# ioat91sam3s4 register map
Registers are 32-bit, access not given, no defined reset value unless marked. A register's access mark holds for its fields unless they carry their own. Addresses are absolute; registers are grouped by the start of their names; [hi:lo] are bit positions; {n}, {i} and the like mark numbered series.

## PIOB
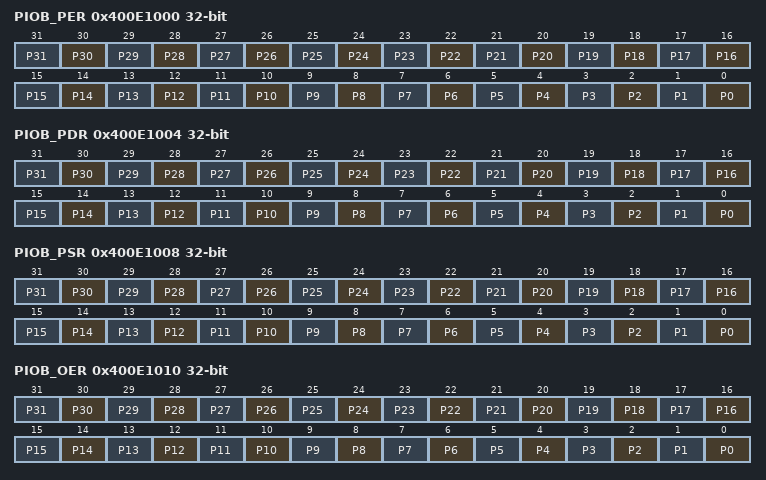
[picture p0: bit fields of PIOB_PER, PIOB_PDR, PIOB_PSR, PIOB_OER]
0x400E1000 PIOB_PER
  [n] P{n} (n=0..31)
0x400E1004 PIOB_PDR
  [n] P{n} (n=0..31)
0x400E1008 PIOB_PSR
  [n] P{n} (n=0..31)
0x400E1010 PIOB_OER
  [n] P{n} (n=0..31)
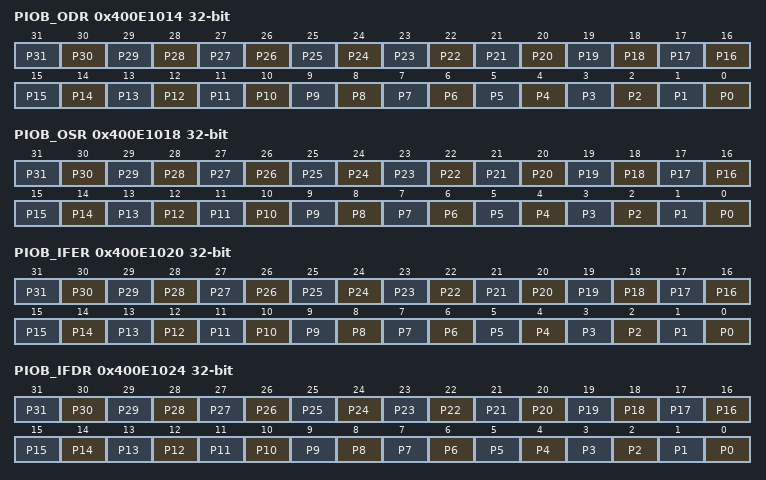
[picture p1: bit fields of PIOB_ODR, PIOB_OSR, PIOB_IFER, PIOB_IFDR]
0x400E1014 PIOB_ODR
  [n] P{n} (n=0..31)
0x400E1018 PIOB_OSR
  [n] P{n} (n=0..31)
0x400E1020 PIOB_IFER
  [n] P{n} (n=0..31)
0x400E1024 PIOB_IFDR
  [n] P{n} (n=0..31)
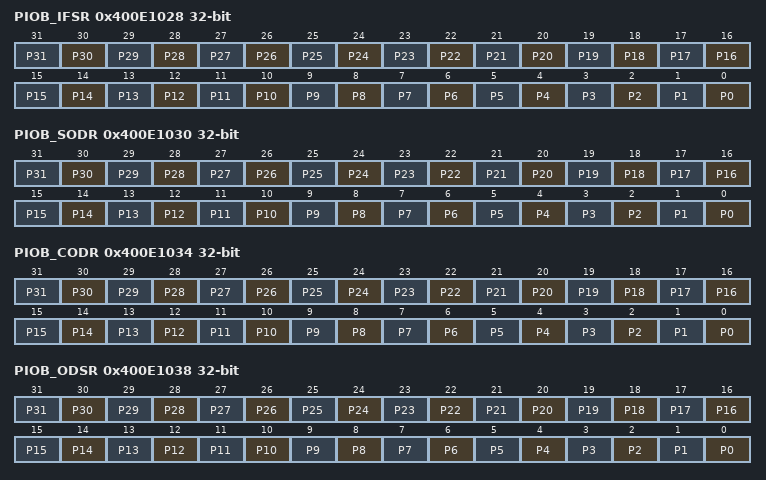
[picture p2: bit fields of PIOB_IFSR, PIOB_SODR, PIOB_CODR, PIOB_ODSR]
0x400E1028 PIOB_IFSR
  [n] P{n} (n=0..31)
0x400E1030 PIOB_SODR
  [n] P{n} (n=0..31)
0x400E1034 PIOB_CODR
  [n] P{n} (n=0..31)
0x400E1038 PIOB_ODSR
  [n] P{n} (n=0..31)
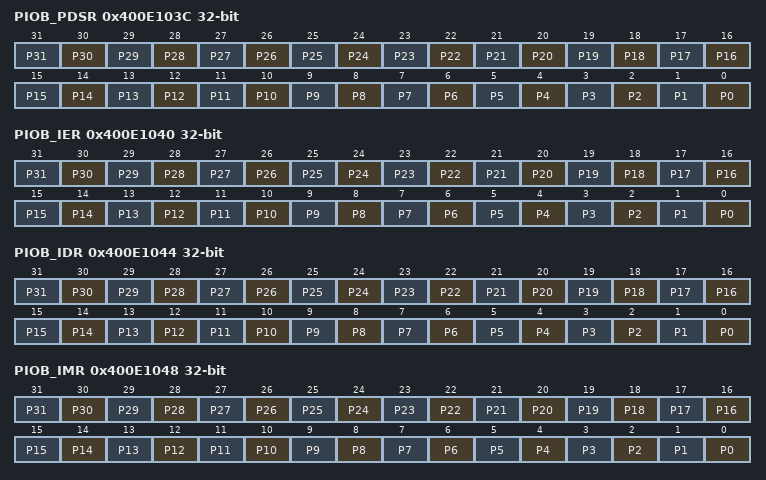
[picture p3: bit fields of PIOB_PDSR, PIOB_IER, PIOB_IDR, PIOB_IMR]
0x400E103C PIOB_PDSR
  [n] P{n} (n=0..31)
0x400E1040 PIOB_IER
  [n] P{n} (n=0..31)
0x400E1044 PIOB_IDR
  [n] P{n} (n=0..31)
0x400E1048 PIOB_IMR
  [n] P{n} (n=0..31)
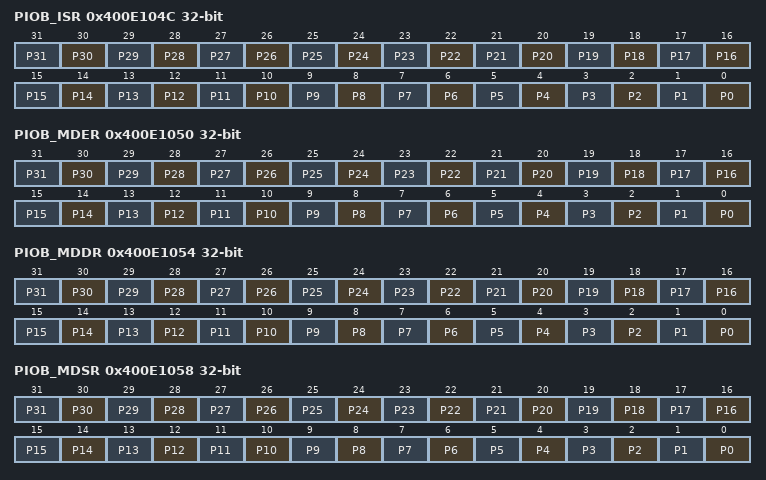
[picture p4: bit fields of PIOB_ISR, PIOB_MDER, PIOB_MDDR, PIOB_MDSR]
0x400E104C PIOB_ISR
  [n] P{n} (n=0..31)
0x400E1050 PIOB_MDER
  [n] P{n} (n=0..31)
0x400E1054 PIOB_MDDR
  [n] P{n} (n=0..31)
0x400E1058 PIOB_MDSR
  [n] P{n} (n=0..31)
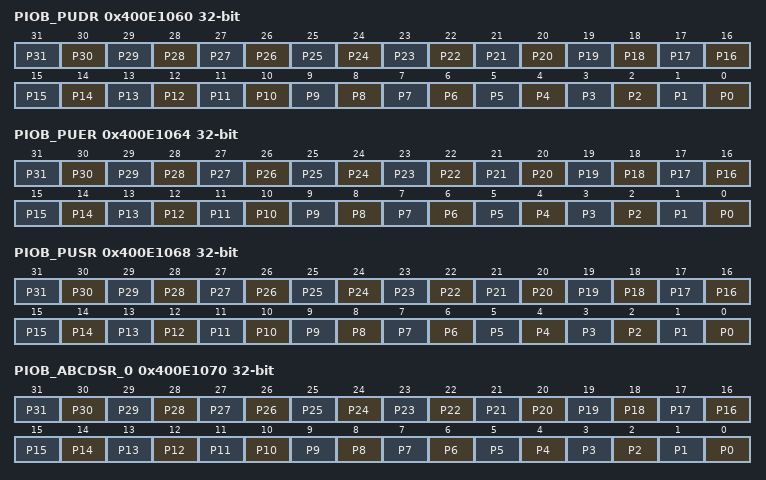
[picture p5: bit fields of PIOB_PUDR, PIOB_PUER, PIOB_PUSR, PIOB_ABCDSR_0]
0x400E1060 PIOB_PUDR
  [n] P{n} (n=0..31)
0x400E1064 PIOB_PUER
  [n] P{n} (n=0..31)
0x400E1068 PIOB_PUSR
  [n] P{n} (n=0..31)
0x400E1070 PIOB_ABCDSR_0
  [n] P{n} (n=0..31)
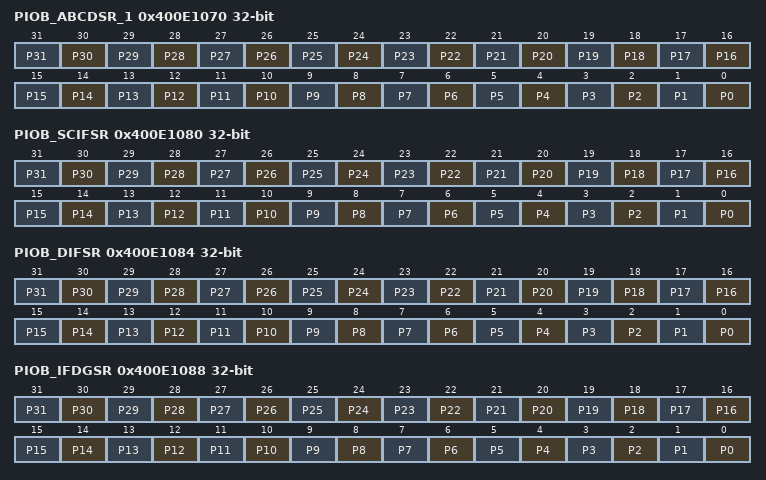
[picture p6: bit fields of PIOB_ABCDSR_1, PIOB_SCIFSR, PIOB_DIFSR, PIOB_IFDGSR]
0x400E1070 PIOB_ABCDSR_1
  [n] P{n} (n=0..31)
0x400E1080 PIOB_SCIFSR
  [n] P{n} (n=0..31)
0x400E1084 PIOB_DIFSR
  [n] P{n} (n=0..31)
0x400E1088 PIOB_IFDGSR
  [n] P{n} (n=0..31)
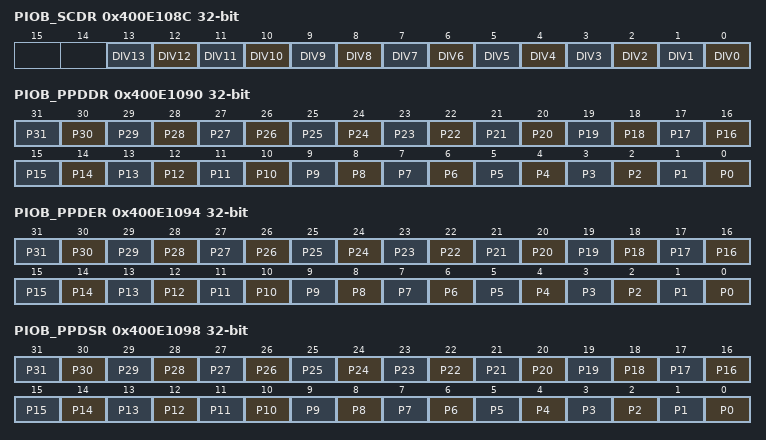
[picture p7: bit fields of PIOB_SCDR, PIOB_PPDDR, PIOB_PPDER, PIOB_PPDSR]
0x400E108C PIOB_SCDR
  [n] DIV{n} (n=0..13)
0x400E1090 PIOB_PPDDR
  [n] P{n} (n=0..31)
0x400E1094 PIOB_PPDER
  [n] P{n} (n=0..31)
0x400E1098 PIOB_PPDSR
  [n] P{n} (n=0..31)
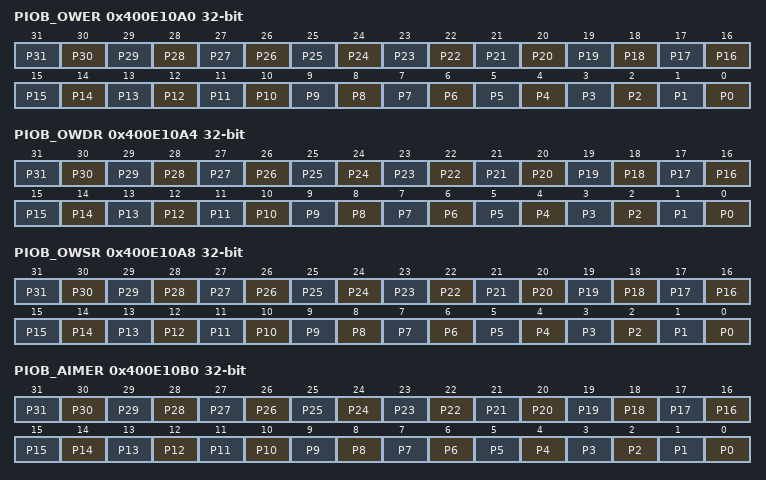
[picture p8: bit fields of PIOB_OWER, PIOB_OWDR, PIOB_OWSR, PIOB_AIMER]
0x400E10A0 PIOB_OWER
  [n] P{n} (n=0..31)
0x400E10A4 PIOB_OWDR
  [n] P{n} (n=0..31)
0x400E10A8 PIOB_OWSR
  [n] P{n} (n=0..31)
0x400E10B0 PIOB_AIMER
  [n] P{n} (n=0..31)
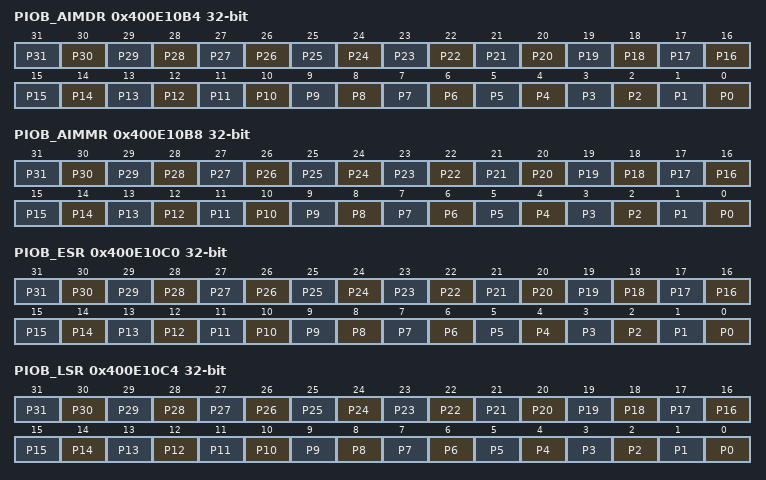
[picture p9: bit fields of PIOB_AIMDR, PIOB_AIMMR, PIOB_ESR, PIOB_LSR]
0x400E10B4 PIOB_AIMDR
  [n] P{n} (n=0..31)
0x400E10B8 PIOB_AIMMR
  [n] P{n} (n=0..31)
0x400E10C0 PIOB_ESR
  [n] P{n} (n=0..31)
0x400E10C4 PIOB_LSR
  [n] P{n} (n=0..31)
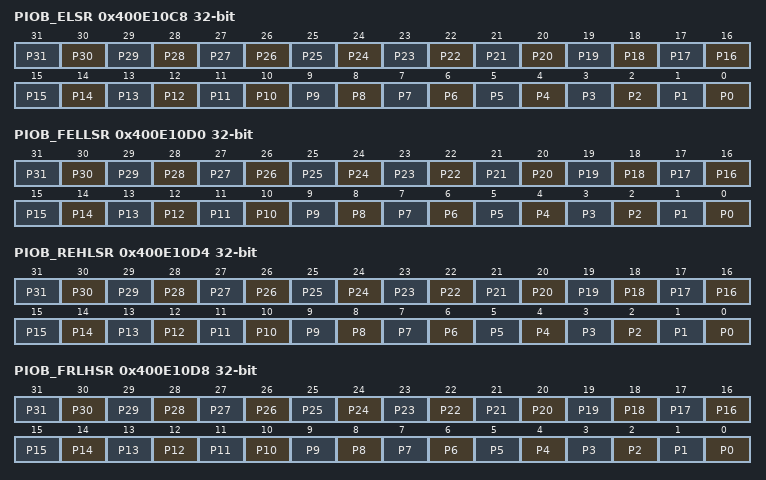
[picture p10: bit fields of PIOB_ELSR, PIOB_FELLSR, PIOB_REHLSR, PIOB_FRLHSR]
0x400E10C8 PIOB_ELSR
  [n] P{n} (n=0..31)
0x400E10D0 PIOB_FELLSR
  [n] P{n} (n=0..31)
0x400E10D4 PIOB_REHLSR
  [n] P{n} (n=0..31)
0x400E10D8 PIOB_FRLHSR
  [n] P{n} (n=0..31)
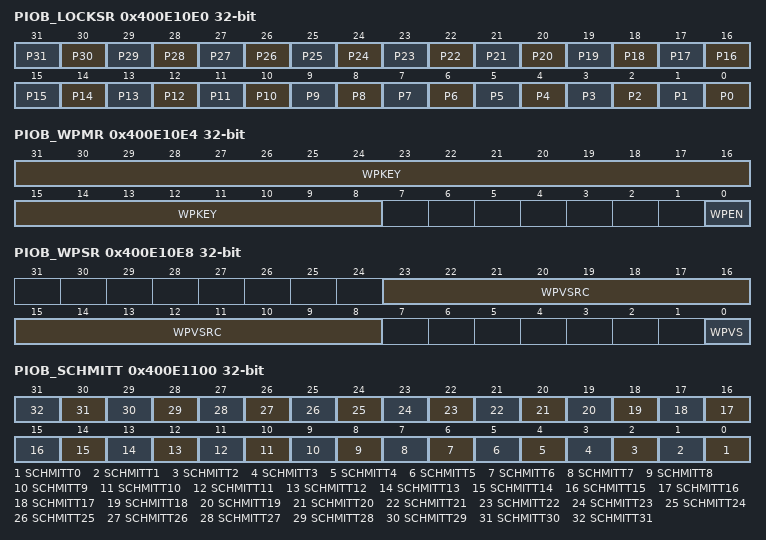
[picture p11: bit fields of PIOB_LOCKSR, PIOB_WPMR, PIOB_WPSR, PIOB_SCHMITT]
0x400E10E0 PIOB_LOCKSR
  [n] P{n} (n=0..31)
0x400E10E4 PIOB_WPMR
  [31:8] WPKEY, [0] WPEN
0x400E10E8 PIOB_WPSR
  [23:8] WPVSRC, [0] WPVS
0x400E1100 PIOB_SCHMITT
  [n] SCHMITT{n} (n=0..31)
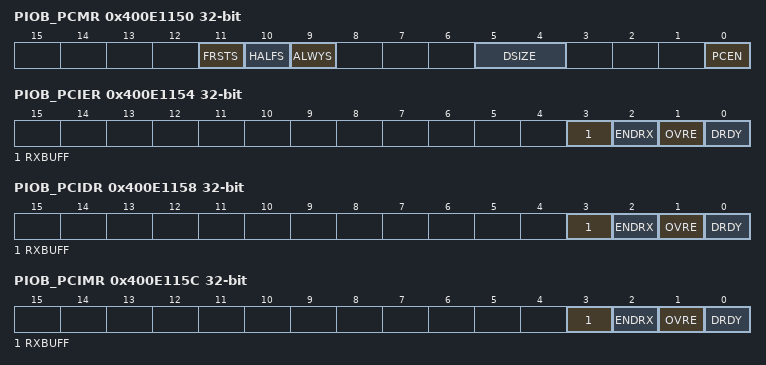
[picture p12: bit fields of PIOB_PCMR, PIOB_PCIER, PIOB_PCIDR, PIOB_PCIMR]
0x400E1150 PIOB_PCMR
  [11] FRSTS, [10] HALFS, [9] ALWYS, [5:4] DSIZE, [0] PCEN
0x400E1154 PIOB_PCIER
  [3] RXBUFF, [2] ENDRX, [1] OVRE, [0] DRDY
0x400E1158 PIOB_PCIDR
  [3] RXBUFF, [2] ENDRX, [1] OVRE, [0] DRDY
0x400E115C PIOB_PCIMR
  [3] RXBUFF, [2] ENDRX, [1] OVRE, [0] DRDY
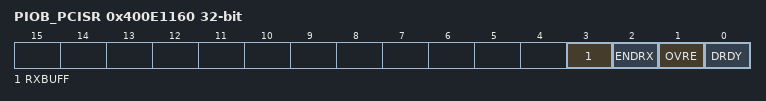
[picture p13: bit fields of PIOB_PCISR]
0x400E1160 PIOB_PCISR
  [3] RXBUFF, [2] ENDRX, [1] OVRE, [0] DRDY
0x400E1164 PIOB_PCRHR
  [31:0] RDATA

## PIOC
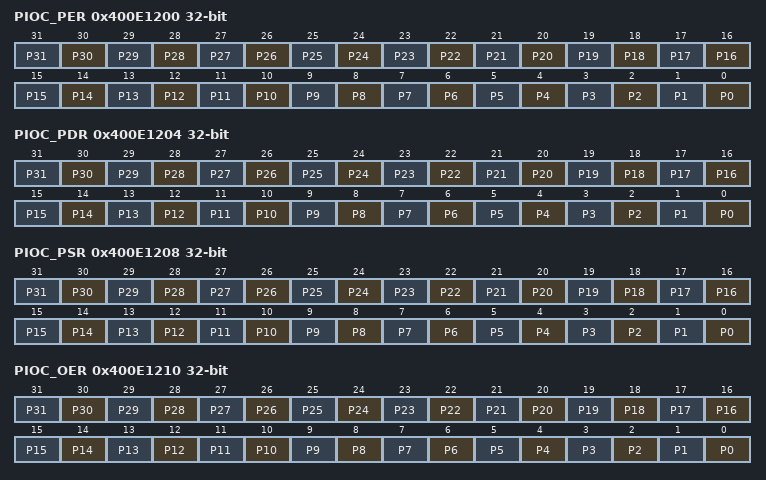
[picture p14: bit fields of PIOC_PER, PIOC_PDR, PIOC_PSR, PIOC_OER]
0x400E1200 PIOC_PER
  [n] P{n} (n=0..31)
0x400E1204 PIOC_PDR
  [n] P{n} (n=0..31)
0x400E1208 PIOC_PSR
  [n] P{n} (n=0..31)
0x400E1210 PIOC_OER
  [n] P{n} (n=0..31)
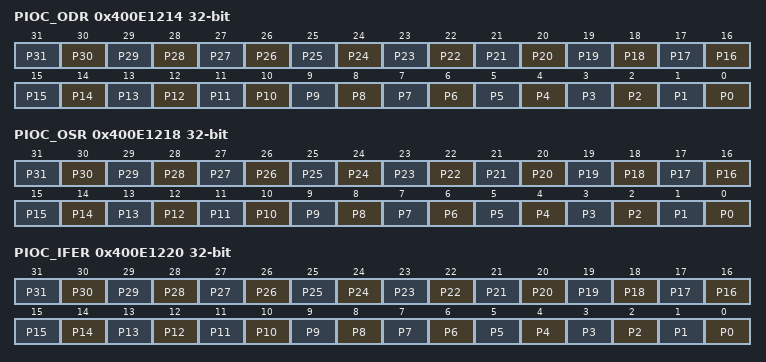
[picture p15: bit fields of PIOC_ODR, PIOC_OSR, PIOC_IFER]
0x400E1214 PIOC_ODR
  [n] P{n} (n=0..31)
0x400E1218 PIOC_OSR
  [n] P{n} (n=0..31)
0x400E1220 PIOC_IFER
  [n] P{n} (n=0..31)
0x400E1224 PIOC_IFDR
  [n] P{n} (n=0..31)
0x400E1228 PIOC_IFSR
  [n] P{n} (n=0..31)
0x400E1230 PIOC_SODR
  [n] P{n} (n=0..31)
0x400E1234 PIOC_CODR
  [n] P{n} (n=0..31)
0x400E1238 PIOC_ODSR
  [n] P{n} (n=0..31)
0x400E123C PIOC_PDSR
  [n] P{n} (n=0..31)
0x400E1240 PIOC_IER
  [n] P{n} (n=0..31)
0x400E1244 PIOC_IDR
  [n] P{n} (n=0..31)
0x400E1248 PIOC_IMR
  [n] P{n} (n=0..31)
0x400E124C PIOC_ISR
  [n] P{n} (n=0..31)
0x400E1250 PIOC_MDER
  [n] P{n} (n=0..31)
0x400E1254 PIOC_MDDR
  [n] P{n} (n=0..31)
0x400E1258 PIOC_MDSR
  [n] P{n} (n=0..31)
0x400E1260 PIOC_PUDR
  [n] P{n} (n=0..31)
0x400E1264 PIOC_PUER
  [n] P{n} (n=0..31)
0x400E1268 PIOC_PUSR
  [n] P{n} (n=0..31)
0x400E1270 PIOC_ABCDSR_0
  [n] P{n} (n=0..31)
0x400E1270 PIOC_ABCDSR_1
  [n] P{n} (n=0..31)
0x400E1280 PIOC_SCIFSR
  [n] P{n} (n=0..31)
0x400E1284 PIOC_DIFSR
  [n] P{n} (n=0..31)
0x400E1288 PIOC_IFDGSR
  [n] P{n} (n=0..31)
0x400E128C PIOC_SCDR
  [n] DIV{n} (n=0..13)
0x400E1290 PIOC_PPDDR
  [n] P{n} (n=0..31)
0x400E1294 PIOC_PPDER
  [n] P{n} (n=0..31)
0x400E1298 PIOC_PPDSR
  [n] P{n} (n=0..31)
0x400E12A0 PIOC_OWER
  [n] P{n} (n=0..31)
0x400E12A4 PIOC_OWDR
  [n] P{n} (n=0..31)
0x400E12A8 PIOC_OWSR
  [n] P{n} (n=0..31)
0x400E12B0 PIOC_AIMER
  [n] P{n} (n=0..31)
0x400E12B4 PIOC_AIMDR
  [n] P{n} (n=0..31)
0x400E12B8 PIOC_AIMMR
  [n] P{n} (n=0..31)
0x400E12C0 PIOC_ESR
  [n] P{n} (n=0..31)
0x400E12C4 PIOC_LSR
  [n] P{n} (n=0..31)
0x400E12C8 PIOC_ELSR
  [n] P{n} (n=0..31)
0x400E12D0 PIOC_FELLSR
  [n] P{n} (n=0..31)
0x400E12D4 PIOC_REHLSR
  [n] P{n} (n=0..31)
0x400E12D8 PIOC_FRLHSR
  [n] P{n} (n=0..31)
0x400E12E0 PIOC_LOCKSR
  [n] P{n} (n=0..31)
0x400E12E4 PIOC_WPMR
  [31:8] WPKEY, [0] WPEN
0x400E12E8 PIOC_WPSR
  [23:8] WPVSRC, [0] WPVS
0x400E1300 PIOC_SCHMITT
  [n] SCHMITT{n} (n=0..31)
0x400E1350 PIOC_PCMR
  [11] FRSTS, [10] HALFS, [9] ALWYS, [5:4] DSIZE, [0] PCEN
0x400E1354 PIOC_PCIER
  [3] RXBUFF, [2] ENDRX, [1] OVRE, [0] DRDY
0x400E1358 PIOC_PCIDR
  [3] RXBUFF, [2] ENDRX, [1] OVRE, [0] DRDY
0x400E135C PIOC_PCIMR
  [3] RXBUFF, [2] ENDRX, [1] OVRE, [0] DRDY
0x400E1360 PIOC_PCISR
  [3] RXBUFF, [2] ENDRX, [1] OVRE, [0] DRDY
0x400E1364 PIOC_PCRHR
  [31:0] RDATA

## RSTC
0x400E1400 RSTC_CR
  [31:24] KEY, [3] EXTRST, [2] PERRST, [0] PROCRST
0x400E1404 RSTC_SR
  [17] SRCMP, [16] NRSTL, [10:8] RSTTYP, [0] URSTS
0x400E1408 RSTC_MR
  [31:24] KEY, [11:8] ERSTL, [4] URSTIEN, [0] URSTEN

## SUPC
0x400E1410 SUPC_CR
  [31:24] KEY, [3] XTALSEL, [2] VROFF
0x400E1414 SUPC_SMMR
  [13] SMIEN, [12] SMRSTEN, [10:8] SMSMPL, [3:0] SMTH
0x400E1418 SUPC_MR
  [31:24] KEY, [20] OSCBYPASS, [14] ONREG, [13] BODDIS, [12] BODRSTEN
0x400E141C SUPC_WUMR
  [14:12] WKUPDBC, [3] RTCEN, [2] RTTEN, [1] SMEN
0x400E1420 SUPC_WUIR
  [n+16] WKUPT{n} (n=0..15), [n] WKUPEN{n} (n=0..15)
0x400E1424 SUPC_SR
  [n+16] WKUPIS{n} (n=0..15), [7] OSCSEL, [6] SMOS, [5] SMS, [4] SMRSTS, [3] BODRSTS, [2] SMWS, [1] WKUPS

## RTT
0x400E1430 RTT_MR
  [18] RTTRST, [17] RTTINCIEN, [16] ALMIEN, [15:0] RTPRES
0x400E1434 RTT_AR
  [31:0] ALMV
0x400E1438 RTT_VR
  [31:0] CRTV
0x400E143C RTT_SR
  [1] RTTINC, [0] ALMS

## WDT
0x400E1450 WDT_CR
  [31:24] KEY, [0] WDRSTT
0x400E1454 WDT_MR
  [29] WDIDLEHLT, [28] WDDBGHLT, [27:16] WDD, [15] WDDIS, [14] WDRPROC, [13] WDRSTEN, [12] WDFIEN, [11:0] WDV
0x400E1458 WDT_SR
  [1] WDERR, [0] WDUNF

## RTC
0x400E1460 RTC_CR
  [17:16] CALEVSEL, [9:8] TIMEVSEL, [1] UPDCAL, [0] UPDTIM
0x400E1464 RTC_MR
  [0] HRMOD
0x400E1468 RTC_TIMR
  [22] AMPM, [21:16] HOUR, [14:8] MIN, [6:0] SEC
0x400E146C RTC_CALR
  [29:24] DATE, [23:21] DAY, [20:16] MONTH, [15:8] YEAR, [6:0] CENT
0x400E1470 RTC_TIMALR
  [23] HOUREN, [22] AMPM, [21:16] HOUR, [15] MINEN, [14:8] MIN, [7] SECEN, [6:0] SEC
0x400E1474 RTC_CALALR
  [31] DATEEN, [29:24] DATE, [23] MTHEN, [20:16] MONTH
0x400E1478 RTC_SR
  [4] CALEV, [3] TIMEV, [2] SEC, [1] ALARM, [0] ACKUPD
0x400E147C RTC_SCCR
  [4] CALCLR, [3] TIMCLR, [2] SECCLR, [1] ALRCLR, [0] ACKCLR
0x400E1480 RTC_IER
  [4] CALEN, [3] TIMEN, [2] SECEN, [1] ALREN, [0] ACKEN
0x400E1484 RTC_IDR
  [4] CALDIS, [3] TIMDIS, [2] SECDIS, [1] ALRDIS, [0] ACKDIS
0x400E1488 RTC_IMR
  [4] CAL, [3] TIM, [2] SEC, [1] ALR, [0] ACK
0x400E148C RTC_VER
  [3] NVCALALR, [2] NVTIMALR, [1] NVCAL, [0] NVTIM

## GPBR
{0x400E1490+4i} GPBR_GPBR{i} (i=0..3)
  [31:0] GPBR_VALUE{i}
